VERSION ""

NS_ :

BS_:

BU_: ECU_Motor ECU_Battery ECU_Sensors ECU_Display

BO_ 128 MotorStatus: 3 ECU_Motor
 SG_ MotorRPM : 0|16@1+ (1,0) [0|8000] "rpm" ECU_Display
 SG_ MotorTemp : 16|8@1+ (1,-40) [-40|215] "°C" ECU_Display

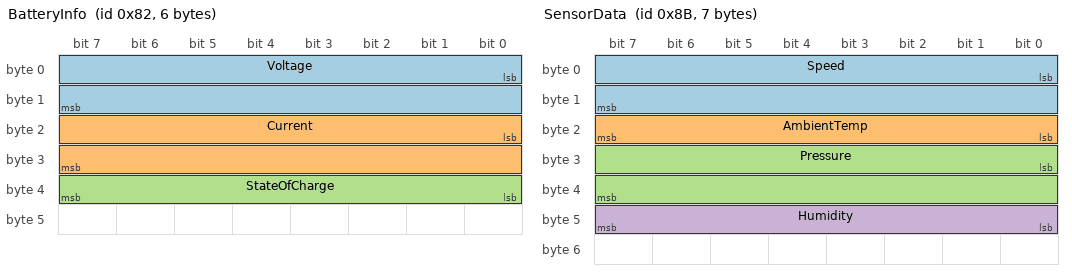
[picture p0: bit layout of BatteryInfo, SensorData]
BO_ 130 BatteryInfo: 6 ECU_Battery
 SG_ Voltage : 0|16@1+ (0.01,0) [0|655.35] "V" ECU_Display
 SG_ Current : 16|16@1- (0.1,0) [-3276.8|3276.7] "A" ECU_Display
 SG_ StateOfCharge : 32|8@1+ (0.5,0) [0|100] "%" ECU_Display

BO_ 139 SensorData: 7 ECU_Sensors
 SG_ Speed : 0|16@1+ (0.01,0) [0|300] "km/h" ECU_Display
 SG_ AmbientTemp : 16|8@1+ (1,-40) [-40|100] "°C" ECU_Display
 SG_ Pressure : 24|16@1+ (0.1,0) [0|6553.5] "kPa" ECU_Display
 SG_ Humidity : 40|8@1+ (0.5,0) [0|100] "%" ECU_Display

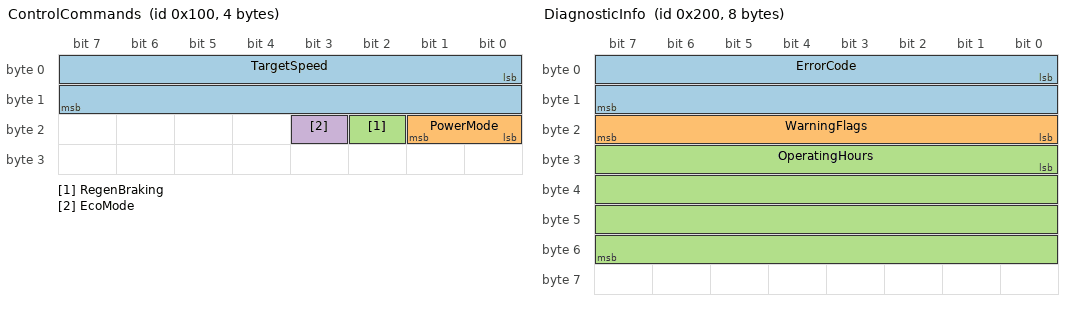
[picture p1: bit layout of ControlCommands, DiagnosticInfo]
BO_ 256 ControlCommands: 4 ECU_Display
 SG_ TargetSpeed : 0|16@1+ (0.1,0) [0|200] "km/h" ECU_Motor
 SG_ PowerMode : 16|2@1+ (1,0) [0|3] "" ECU_Motor
 SG_ RegenBraking : 18|1@1+ (1,0) [0|1] "" ECU_Motor
 SG_ EcoMode : 19|1@1+ (1,0) [0|1] "" ECU_Motor

BO_ 512 DiagnosticInfo: 8 ECU_Motor
 SG_ ErrorCode : 0|16@1+ (1,0) [0|65535] "" ECU_Display
 SG_ WarningFlags : 16|8@1+ (1,0) [0|255] "" ECU_Display
 SG_ OperatingHours : 24|32@1+ (0.1,0) [0|429496729.5] "h" ECU_Display

CM_ BO_ 128 "Motor status information including RPM and temperature";
CM_ SG_ 128 MotorRPM "Current motor rotations per minute";
CM_ SG_ 128 MotorTemp "Motor temperature in Celsius";
CM_ BO_ 130 "Battery pack information";
CM_ SG_ 130 Voltage "Battery voltage";
CM_ SG_ 130 Current "Battery current (positive=charging, negative=discharging)";
CM_ SG_ 130 StateOfCharge "Battery state of charge percentage";
CM_ BO_ 139 "Environmental and vehicle sensor data";
CM_ BO_ 256 "Control commands from display unit";
CM_ BO_ 512 "Diagnostic and error information";

BA_DEF_ "BusType" STRING;
BA_DEF_ BO_ "GenMsgCycleTime" INT 0 10000;

BA_DEF_DEF_ "BusType" "CAN";
BA_DEF_DEF_ "GenMsgCycleTime" 0;

BA_ "GenMsgCycleTime" BO_ 128 100;
BA_ "GenMsgCycleTime" BO_ 130 200;
BA_ "GenMsgCycleTime" BO_ 139 50;
BA_ "GenMsgCycleTime" BO_ 256 100;
BA_ "GenMsgCycleTime" BO_ 512 1000;

VAL_ 256 PowerMode 0 "Eco" 1 "Normal" 2 "Sport" 3 "Max";
VAL_ 256 RegenBraking 0 "Off" 1 "On";
VAL_ 256 EcoMode 0 "Off" 1 "On";
